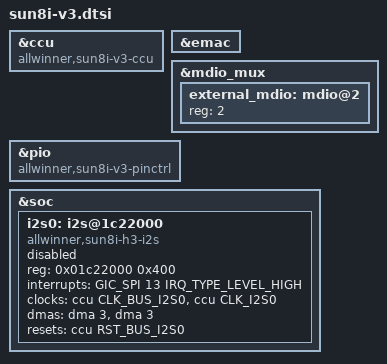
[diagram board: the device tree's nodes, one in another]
// SPDX-License-Identifier: (GPL-2.0+ OR MIT)
/*
 * Copyright (C) 2019 Icenowy Zheng <icenowy@aosc.io>
 */

#include "sun8i-v3s.dtsi"

&ccu {
	compatible = "allwinner,sun8i-v3-ccu";
};

&emac {
	/delete-property/ phy-handle;
	/delete-property/ phy-mode;
};

&mdio_mux {
	external_mdio: mdio@2 {
		reg = <2>;
		#address-cells = <1>;
		#size-cells = <0>;
	};
};

&pio {
	compatible = "allwinner,sun8i-v3-pinctrl";
};

&soc {
		i2s0: i2s@1c22000 {
			#sound-dai-cells = <0>;
			compatible = "allwinner,sun8i-h3-i2s";
			reg = <0x01c22000 0x400>;
			interrupts = <GIC_SPI 13 IRQ_TYPE_LEVEL_HIGH>;
			clocks = <&ccu CLK_BUS_I2S0>, <&ccu CLK_I2S0>;
			clock-names = "apb", "mod";
			dmas = <&dma 3>, <&dma 3>;
			resets = <&ccu RST_BUS_I2S0>;
			dma-names = "rx", "tx";
			status = "disabled";
		};
};
